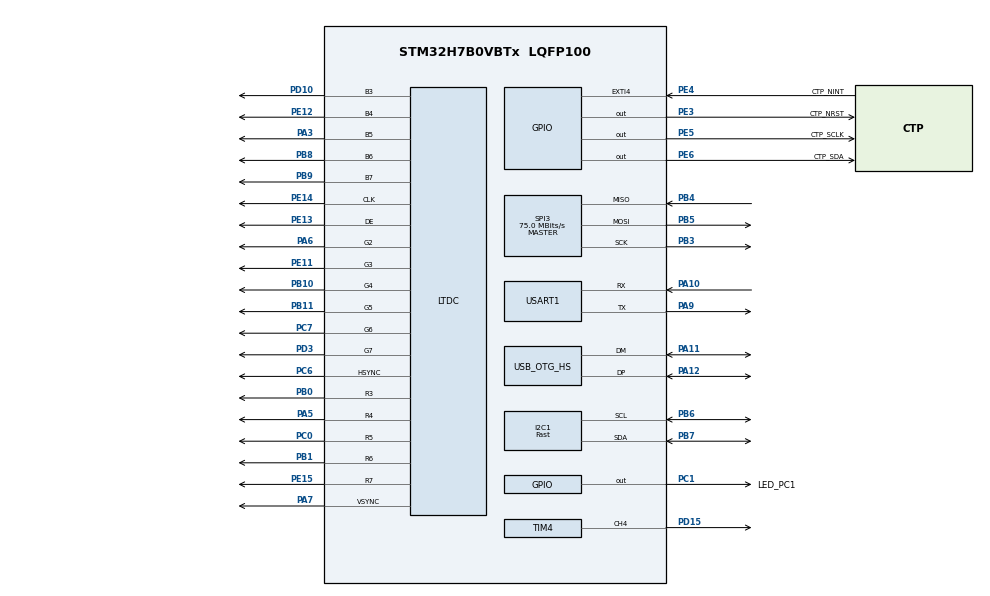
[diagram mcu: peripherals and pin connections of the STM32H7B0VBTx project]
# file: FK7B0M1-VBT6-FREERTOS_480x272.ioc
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CORTEX_M7.AccessPermission_S-Cortex_Memory_Protection_Unit_Region1_Settings_S=MPU_REGION_FULL_ACCESS
CORTEX_M7.AccessPermission_Spec=MPU_REGION_FULL_ACCESS
CORTEX_M7.BaseAddress_S-Cortex_Memory_Protection_Unit_Region1_Settings_S=0x24080000
CORTEX_M7.BaseAddress_Spec=0x24000000
CORTEX_M7.CPU_DCache=Enabled
CORTEX_M7.CPU_ICache=Enabled
CORTEX_M7.DisableExec_S-Cortex_Memory_Protection_Unit_Region1_Settings_S=MPU_INSTRUCTION_ACCESS_DISABLE
CORTEX_M7.DisableExec_Spec=MPU_INSTRUCTION_ACCESS_DISABLE
CORTEX_M7.Enable_S-Cortex_Memory_Protection_Unit_Region1_Settings_S=MPU_REGION_ENABLE
CORTEX_M7.IsBufferable_S-Cortex_Memory_Protection_Unit_Region1_Settings_S=MPU_ACCESS_BUFFERABLE
CORTEX_M7.IsBufferable_Spec=MPU_ACCESS_NOT_BUFFERABLE
CORTEX_M7.IsCacheable_S-Cortex_Memory_Protection_Unit_Region1_Settings_S=MPU_ACCESS_CACHEABLE
CORTEX_M7.IsCacheable_Spec=MPU_ACCESS_NOT_CACHEABLE
CORTEX_M7.IsShareable_S-Cortex_Memory_Protection_Unit_Region1_Settings_S=MPU_ACCESS_NOT_SHAREABLE
CORTEX_M7.IsShareable_Spec=MPU_ACCESS_SHAREABLE
CORTEX_M7.Size_S-Cortex_Memory_Protection_Unit_Region1_Settings_S=MPU_REGION_SIZE_512KB
CORTEX_M7.Size_Spec=MPU_REGION_SIZE_512KB
CORTEX_M7.SubRegionDisable_Spec=0x00
CORTEX_M7.TypeExtField_S-Cortex_Memory_Protection_Unit_Region1_Settings_S=MPU_TEX_LEVEL1
CORTEX_M7.TypeExtField_Spec=MPU_TEX_LEVEL1
CORTEX_M7.default_mode_Activation=1
FREERTOS.Tasks01=defaultTask,24,128,StartDefaultTask,Default,NULL,Dynamic,NULL,NULL
FREERTOS.configENABLE_FPU=1
FREERTOS.configTOTAL_HEAP_SIZE=32768
I2C1.I2C_Speed_Mode=I2C_Fast
I2C1.Timing=0x00D04BFF
LTDC.ActiveH=272
LTDC.ActiveW=480
LTDC.Alpha_L0=255
LTDC.BlendingFactor1_L0=LTDC_BLENDING_FACTOR1_CA
LTDC.BlendingFactor2_L0=LTDC_BLENDING_FACTOR2_CA
LTDC.DEPolarity=LTDC_DEPOLARITY_AL
LTDC.FBStartAdress_L0=0x24000000
LTDC.HBP=44
LTDC.HFP=8
LTDC.HSync=4
LTDC.ImageHeight_L0=272
LTDC.ImageWidth_L0=480
LTDC.Layers=0
LTDC.PCPolarity=LTDC_PCPOLARITY_IIPC
LTDC.PixelFormat_L0=LTDC_PIXEL_FORMAT_RGB565
LTDC.VBP=13
LTDC.VFP=2
LTDC.VSync=4
LTDC.WindowX1_L0=479
LTDC.WindowY1_L0=271
Mcu.Family=STM32H7
Mcu.Name=STM32H7B0VBTx
Mcu.Package=LQFP100
NVIC.DMA2D_IRQn=true\:5\:0\:false\:false\:true\:true\:true\:true\:true
NVIC.EXTI4_IRQn=true\:5\:0\:true\:false\:true\:false\:true\:true\:true
NVIC.I2C1_ER_IRQn=true\:5\:0\:false\:false\:true\:true\:true\:true\:true
NVIC.I2C1_EV_IRQn=true\:5\:0\:false\:false\:true\:true\:true\:true\:true
NVIC.LTDC_IRQn=true\:5\:0\:false\:false\:true\:true\:true\:true\:true
NVIC.OTG_HS_IRQn=true\:5\:0\:false\:false\:true\:true\:false\:true\:true
NVIC.PriorityGroup=NVIC_PRIORITYGROUP_4
NVIC.SPI3_IRQn=true\:5\:0\:false\:false\:true\:true\:true\:true\:true
NVIC.TIM8_UP_TIM13_IRQn=true\:15\:0\:false\:false\:true\:false\:false\:true\:true
NVIC.TimeBase=TIM8_UP_TIM13_IRQn
NVIC.TimeBaseIP=TIM8
PA1.Signal=LTDC_R2
PA10.Mode=Asynchronous
PA10.Signal=USART1_RX
PA11.Mode=Device_Only_FS
PA11.Signal=USB_OTG_HS_DM
PA12.Mode=Device_Only_FS
PA12.Signal=USB_OTG_HS_DP
PA13.Mode=Serial_Wire
PA13.Signal=DEBUG_JTMS-SWDIO
PA14.Mode=Serial_Wire
PA14.Signal=DEBUG_JTCK-SWCLK
PA15.Signal=SPI3_NSS
PA2.Signal=LTDC_R1
PA3.GPIO_Speed=GPIO_SPEED_FREQ_VERY_HIGH
PA3.Mode=RGB565
PA3.Signal=LTDC_B5
PA5.GPIO_Speed=GPIO_SPEED_FREQ_VERY_HIGH
PA5.Mode=RGB565
PA5.Signal=LTDC_R4
PA6.GPIO_Speed=GPIO_SPEED_FREQ_VERY_HIGH
PA6.Mode=RGB565
PA6.Signal=LTDC_G2
PA7.GPIO_Speed=GPIO_SPEED_FREQ_VERY_HIGH
PA7.Mode=RGB565
PA7.Signal=LTDC_VSYNC
PA9.Mode=Asynchronous
PA9.Signal=USART1_TX
PB0.GPIO_Speed=GPIO_SPEED_FREQ_VERY_HIGH
PB0.Mode=RGB565
PB0.Signal=LTDC_R3
PB1.GPIO_Speed=GPIO_SPEED_FREQ_VERY_HIGH
PB1.Mode=RGB565
PB1.Signal=LTDC_R6
PB10.GPIO_Speed=GPIO_SPEED_FREQ_VERY_HIGH
PB10.Mode=RGB565
PB10.Signal=LTDC_G4
PB11.GPIO_Speed=GPIO_SPEED_FREQ_VERY_HIGH
PB11.Mode=RGB565
PB11.Signal=LTDC_G5
PB3.Mode=Full_Duplex_Master
PB3.Signal=SPI3_SCK
PB4.Mode=Full_Duplex_Master
PB4.Signal=SPI3_MISO
PB5.Mode=Full_Duplex_Master
PB5.Signal=SPI3_MOSI
PB6.Mode=I2C
PB6.Signal=I2C1_SCL
PB7.Mode=I2C
PB7.Signal=I2C1_SDA
PB8.GPIO_FM8=__NULL
PB8.GPIO_Speed=GPIO_SPEED_FREQ_VERY_HIGH
PB8.Mode=RGB565
PB8.Signal=LTDC_B6
PB9.GPIO_Speed=GPIO_SPEED_FREQ_VERY_HIGH
PB9.Mode=RGB565
PB9.Signal=LTDC_B7
PC0.GPIO_Speed=GPIO_SPEED_FREQ_VERY_HIGH
PC0.Mode=RGB565
PC0.Signal=LTDC_R5
PC1.GPIO_Label=LED_PC1
PC1.Signal=GPIO_Output
PC14-OSC32_IN.Mode=LSE-External-Oscillator
PC14-OSC32_IN.Signal=RCC_OSC32_IN
PC15-OSC32_OUT.Mode=LSE-External-Oscillator
PC15-OSC32_OUT.Signal=RCC_OSC32_OUT
PC6.GPIO_Speed=GPIO_SPEED_FREQ_VERY_HIGH
PC6.Mode=RGB565
PC6.Signal=LTDC_HSYNC
PC7.GPIO_Speed=GPIO_SPEED_FREQ_VERY_HIGH
PC7.Mode=RGB565
PC7.Signal=LTDC_G6
PD10.GPIO_Speed=GPIO_SPEED_FREQ_VERY_HIGH
PD10.Mode=RGB565
PD10.Signal=LTDC_B3
PD15.Signal=S_TIM4_CH4
PD3.GPIO_Speed=GPIO_SPEED_FREQ_VERY_HIGH
PD3.Mode=RGB565
PD3.Signal=LTDC_G7
PD6.Signal=LTDC_B2
PE11.GPIO_Speed=GPIO_SPEED_FREQ_VERY_HIGH
PE11.Mode=RGB565
PE11.Signal=LTDC_G3
PE12.GPIO_Speed=GPIO_SPEED_FREQ_VERY_HIGH
PE12.Mode=RGB565
PE12.Signal=LTDC_B4
PE13.GPIO_Speed=GPIO_SPEED_FREQ_VERY_HIGH
PE13.Mode=RGB565
PE13.Signal=LTDC_DE
PE14.GPIO_Speed=GPIO_SPEED_FREQ_VERY_HIGH
PE14.Mode=RGB565
PE14.Signal=LTDC_CLK
PE15.GPIO_Speed=GPIO_SPEED_FREQ_VERY_HIGH
PE15.Mode=RGB565
PE15.Signal=LTDC_R7
PE3.GPIO_Label=CTP_NRST
PE3.GPIO_PuPd=GPIO_PULLUP
PE3.GPIO_Speed=GPIO_SPEED_FREQ_VERY_HIGH
PE3.Signal=GPIO_Output
PE4.GPIO_Label=CTP_NINT
PE4.GPIO_ModeDefaultEXTI=GPIO_MODE_IT_FALLING
PE4.GPIO_PuPd=GPIO_PULLUP
PE4.Signal=GPXTI4
PE5.GPIO_Label=CTP_SCLK
PE5.GPIO_PuPd=GPIO_PULLUP
PE5.GPIO_Speed=GPIO_SPEED_FREQ_VERY_HIGH
PE5.PinState=GPIO_PIN_SET
PE5.Signal=GPIO_Output
PE6.GPIO_Label=CTP_SDA
PE6.GPIO_PuPd=GPIO_PULLUP
PE6.GPIO_Speed=GPIO_SPEED_FREQ_VERY_HIGH
PE6.PinState=GPIO_PIN_SET
PE6.Signal=GPIO_Output
PH0-OSC_IN.Mode=HSE-External-Oscillator
PH0-OSC_IN.Signal=RCC_OSC_IN
PH1-OSC_OUT.Mode=HSE-External-Oscillator
PH1-OSC_OUT.Signal=RCC_OSC_OUT
ProjectManager.HeapSize=0x200
ProjectManager.StackSize=0x400
ProjectManager.TargetToolchain=Makefile
RCC.ADCFreq_Value=50390625
RCC.APB1Freq_Value=140000000
RCC.APB2Freq_Value=140000000
RCC.APB3Freq_Value=140000000
RCC.APB4Freq_Value=140000000
RCC.CDPPRE=RCC_APB3_DIV2
RCC.CDPPRE1=RCC_APB1_DIV2
RCC.CDPPRE2=RCC_APB2_DIV2
RCC.CortexFreq_Value=280000000
RCC.DIVM1=5
RCC.DIVM3=2
RCC.DIVN1=112
RCC.DIVN3=24
RCC.DIVQ1=12
RCC.DIVR3=25
RCC.HCLKFreq_Value=280000000
RCC.HSE_VALUE=25000000
RCC.PLL2FRACN=0
RCC.PLL3FRACN=0
RCC.PLLFRACN=0
RCC.PLLSourceVirtual=RCC_PLLSOURCE_HSE
RCC.SPI123CLockSelection=RCC_SPI123CLKSOURCE_PLL3
RCC.SRDPPRE=RCC_APB4_DIV2
RCC.SYSCLKFreq_VALUE=280000000
RCC.SYSCLKSource=RCC_SYSCLKSOURCE_PLLCLK
RCC.USBCLockSelection=RCC_USBCLKSOURCE_HSI48
RCC.USBFreq_Value=48000000
SH.S_TIM4_CH4.0=TIM4_CH4,PWM Generation4 CH4
SPI3.CalculateBaudRate=75.0 MBits/s
SPI3.Direction=SPI_DIRECTION_2LINES
SPI3.Mode=SPI_MODE_MASTER
SPI3.VirtualType=VM_MASTER
TIM4.AutoReloadPreload=TIM_AUTORELOAD_PRELOAD_ENABLE
TIM4.Channel-PWM\ Generation4\ CH4=TIM_CHANNEL_4
TIM4.Period=999
TIM4.Prescaler=27
TIM4.Pulse-PWM\ Generation4\ CH4=300
USART1.VirtualMode-Asynchronous=VM_ASYNC
USB_DEVICE.CLASS_NAME_HS=CDC
USB_DEVICE.VirtualMode=Cdc
USB_DEVICE.VirtualModeHS=Cdc_HS
USB_OTG_HS.VirtualMode-Device_Only_FS=Device_Only_FS
VP_DMA2D_VS_DMA2D.Mode=DMA2D_Activate
VP_FREERTOS_VS_CMSIS_V2.Mode=CMSIS_V2
VP_MEMORYMAP_VS_MEMORYMAP.Mode=CurAppReg
VP_SYS_VS_tim8.Mode=TIM8
VP_TIM4_VS_ClockSourceINT.Mode=Internal
VP_USB_DEVICE_VS_USB_DEVICE_CDC_HS.Mode=CDC_HS
board=custom

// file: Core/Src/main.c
/* USER CODE BEGIN Header */
/**
  ******************************************************************************
  * @file           : main.c
  * @brief          : Main program body
  ******************************************************************************
  * @attention
  *
  * Copyright (c) 2026 STMicroelectronics.
  * All rights reserved.
  *
  * This software is licensed under terms that can be found in the LICENSE file
  * in the root directory of this software component.
  * If no LICENSE file comes with this software, it is provided AS-IS.
  *
  ******************************************************************************
  */
/* USER CODE END Header */
#include "main.h"
#include "FreeRTOS.h"
#include "cmsis_os2.h"
#include "usb_device.h"

/* USER CODE BEGIN Includes */
#include "app.h"
/* USER CODE END Includes */

DMA2D_HandleTypeDef hdma2d;

I2C_HandleTypeDef hi2c1;

LTDC_HandleTypeDef hltdc;

SPI_HandleTypeDef hspi3;

TIM_HandleTypeDef htim4;

UART_HandleTypeDef huart1;

/* Definitions for defaultTask */
osThreadId_t defaultTaskHandle;
const osThreadAttr_t defaultTask_attributes = {
  .name = "defaultTask",
  .stack_size = 128 * 4,
  .priority = (osPriority_t) osPriorityNormal,
};

void SystemClock_Config(void);
void PeriphCommonClock_Config(void);
static void MPU_Config(void);
static void MX_GPIO_Init(void);
static void MX_LTDC_Init(void);
static void MX_SPI3_Init(void);
static void MX_USART1_UART_Init(void);
static void MX_I2C1_Init(void);
static void MX_TIM4_Init(void);
static void MX_DMA2D_Init(void);
void StartDefaultTask(void *argument);

int main(void)
{

  /* MPU Configuration--------------------------------------------------------*/
  MPU_Config();

  /* Enable the CPU Cache */

  /* Enable I-Cache---------------------------------------------------------*/
  SCB_EnableICache();

  /* Enable D-Cache---------------------------------------------------------*/
  SCB_EnableDCache();

  /* MCU Configuration--------------------------------------------------------*/

  /* Reset of all peripherals, Initializes the Flash interface and the Systick. */
  HAL_Init();

  /* Configure the system clock */
  SystemClock_Config();

  /* Configure the peripherals common clocks */
  PeriphCommonClock_Config();

  /* Initialize all configured peripherals */
  MX_GPIO_Init();
  MX_LTDC_Init();
  MX_SPI3_Init();
  MX_USART1_UART_Init();
  MX_I2C1_Init();
  MX_TIM4_Init();
  MX_DMA2D_Init();

  /* Init scheduler */
  osKernelInitialize();

  /* USER CODE BEGIN RTOS_MUTEX */
  app_init();
  /* USER CODE END RTOS_MUTEX */

  /* Create the thread(s) */
  /* creation of defaultTask */
  defaultTaskHandle = osThreadNew(StartDefaultTask, NULL, &defaultTask_attributes);

  /* Start scheduler */
  osKernelStart();

  /* We should never get here as control is now taken by the scheduler */

  /* Infinite loop */
  while (1)
  {

  }
}

void SystemClock_Config(void)
{
  RCC_OscInitTypeDef RCC_OscInitStruct = {0};
  RCC_ClkInitTypeDef RCC_ClkInitStruct = {0};

  /*AXI clock gating */
  RCC->CKGAENR = 0xE003FFFF;

  /** Supply configuration update enable
  */
  HAL_PWREx_ConfigSupply(PWR_LDO_SUPPLY);

  /** Configure the main internal regulator output voltage
  */
  __HAL_PWR_VOLTAGESCALING_CONFIG(PWR_REGULATOR_VOLTAGE_SCALE0);

  while(!__HAL_PWR_GET_FLAG(PWR_FLAG_VOSRDY)) {}

  /** Initializes the RCC Oscillators according to the specified parameters
  * in the RCC_OscInitTypeDef structure.
  */
  RCC_OscInitStruct.OscillatorType = RCC_OSCILLATORTYPE_HSI48|RCC_OSCILLATORTYPE_HSE;
  RCC_OscInitStruct.HSEState = RCC_HSE_ON;
  RCC_OscInitStruct.HSI48State = RCC_HSI48_ON;
  RCC_OscInitStruct.PLL.PLLState = RCC_PLL_ON;
  RCC_OscInitStruct.PLL.PLLSource = RCC_PLLSOURCE_HSE;
  RCC_OscInitStruct.PLL.PLLM = 5;
  RCC_OscInitStruct.PLL.PLLN = 112;
  RCC_OscInitStruct.PLL.PLLP = 2;
  RCC_OscInitStruct.PLL.PLLQ = 12;
  RCC_OscInitStruct.PLL.PLLR = 2;
  RCC_OscInitStruct.PLL.PLLRGE = RCC_PLL1VCIRANGE_2;
  RCC_OscInitStruct.PLL.PLLVCOSEL = RCC_PLL1VCOWIDE;
  RCC_OscInitStruct.PLL.PLLFRACN = 0;
  if (HAL_RCC_OscConfig(&RCC_OscInitStruct) != HAL_OK)
  {
    Error_Handler();
  }

  /** Initializes the CPU, AHB and APB buses clocks
  */
  RCC_ClkInitStruct.ClockType = RCC_CLOCKTYPE_HCLK|RCC_CLOCKTYPE_SYSCLK
                              |RCC_CLOCKTYPE_PCLK1|RCC_CLOCKTYPE_PCLK2
                              |RCC_CLOCKTYPE_D3PCLK1|RCC_CLOCKTYPE_D1PCLK1;
  RCC_ClkInitStruct.SYSCLKSource = RCC_SYSCLKSOURCE_PLLCLK;
  RCC_ClkInitStruct.SYSCLKDivider = RCC_SYSCLK_DIV1;
  RCC_ClkInitStruct.AHBCLKDivider = RCC_HCLK_DIV1;
  RCC_ClkInitStruct.APB3CLKDivider = RCC_APB3_DIV2;
  RCC_ClkInitStruct.APB1CLKDivider = RCC_APB1_DIV2;
  RCC_ClkInitStruct.APB2CLKDivider = RCC_APB2_DIV2;
  RCC_ClkInitStruct.APB4CLKDivider = RCC_APB4_DIV2;

  if (HAL_RCC_ClockConfig(&RCC_ClkInitStruct, FLASH_LATENCY_6) != HAL_OK)
  {
    Error_Handler();
  }
}

void PeriphCommonClock_Config(void)
{
  RCC_PeriphCLKInitTypeDef PeriphClkInitStruct = {0};

  /** Initializes the peripherals clock
  */
  PeriphClkInitStruct.PeriphClockSelection = RCC_PERIPHCLK_SPI3|RCC_PERIPHCLK_LTDC;
  PeriphClkInitStruct.PLL3.PLL3M = 2;
  PeriphClkInitStruct.PLL3.PLL3N = 24;
  PeriphClkInitStruct.PLL3.PLL3P = 2;
  PeriphClkInitStruct.PLL3.PLL3Q = 2;
  PeriphClkInitStruct.PLL3.PLL3R = 25;
  PeriphClkInitStruct.PLL3.PLL3RGE = RCC_PLL3VCIRANGE_3;
  PeriphClkInitStruct.PLL3.PLL3VCOSEL = RCC_PLL3VCOWIDE;
  PeriphClkInitStruct.PLL3.PLL3FRACN = 0;
  PeriphClkInitStruct.Spi123ClockSelection = RCC_SPI123CLKSOURCE_PLL3;
  if (HAL_RCCEx_PeriphCLKConfig(&PeriphClkInitStruct) != HAL_OK)
  {
    Error_Handler();
  }
}

static void MX_DMA2D_Init(void)
{

  hdma2d.Instance = DMA2D;
  hdma2d.Init.Mode = DMA2D_M2M;
  hdma2d.Init.ColorMode = DMA2D_OUTPUT_ARGB8888;
  hdma2d.Init.OutputOffset = 0;
  hdma2d.LayerCfg[1].InputOffset = 0;
  hdma2d.LayerCfg[1].InputColorMode = DMA2D_INPUT_ARGB8888;
  hdma2d.LayerCfg[1].AlphaMode = DMA2D_NO_MODIF_ALPHA;
  hdma2d.LayerCfg[1].InputAlpha = 0;
  hdma2d.LayerCfg[1].AlphaInverted = DMA2D_REGULAR_ALPHA;
  hdma2d.LayerCfg[1].RedBlueSwap = DMA2D_RB_REGULAR;
  hdma2d.LayerCfg[1].ChromaSubSampling = DMA2D_NO_CSS;
  if (HAL_DMA2D_Init(&hdma2d) != HAL_OK)
  {
    Error_Handler();
  }
  if (HAL_DMA2D_ConfigLayer(&hdma2d, 1) != HAL_OK)
  {
    Error_Handler();
  }

}

static void MX_I2C1_Init(void)
{

  hi2c1.Instance = I2C1;
  hi2c1.Init.Timing = 0x00D04BFF;
  hi2c1.Init.OwnAddress1 = 0;
  hi2c1.Init.AddressingMode = I2C_ADDRESSINGMODE_7BIT;
  hi2c1.Init.DualAddressMode = I2C_DUALADDRESS_DISABLE;
  hi2c1.Init.OwnAddress2 = 0;
  hi2c1.Init.OwnAddress2Masks = I2C_OA2_NOMASK;
  hi2c1.Init.GeneralCallMode = I2C_GENERALCALL_DISABLE;
  hi2c1.Init.NoStretchMode = I2C_NOSTRETCH_DISABLE;
  if (HAL_I2C_Init(&hi2c1) != HAL_OK)
  {
    Error_Handler();
  }

  /** Configure Analogue filter
  */
  if (HAL_I2CEx_ConfigAnalogFilter(&hi2c1, I2C_ANALOGFILTER_ENABLE) != HAL_OK)
  {
    Error_Handler();
  }

  /** Configure Digital filter
  */
  if (HAL_I2CEx_ConfigDigitalFilter(&hi2c1, 0) != HAL_OK)
  {
    Error_Handler();
  }

}

static void MX_LTDC_Init(void)
{

  LTDC_LayerCfgTypeDef pLayerCfg = {0};

  hltdc.Instance = LTDC;
  hltdc.Init.HSPolarity = LTDC_HSPOLARITY_AL;
  hltdc.Init.VSPolarity = LTDC_VSPOLARITY_AL;
  hltdc.Init.DEPolarity = LTDC_DEPOLARITY_AL;
  hltdc.Init.PCPolarity = LTDC_PCPOLARITY_IIPC;
  hltdc.Init.HorizontalSync = 3;
  hltdc.Init.VerticalSync = 3;
  hltdc.Init.AccumulatedHBP = 47;
  hltdc.Init.AccumulatedVBP = 16;
  hltdc.Init.AccumulatedActiveW = 527;
  hltdc.Init.AccumulatedActiveH = 288;
  hltdc.Init.TotalWidth = 535;
  hltdc.Init.TotalHeigh = 290;
  hltdc.Init.Backcolor.Blue = 0;
  hltdc.Init.Backcolor.Green = 0;
  hltdc.Init.Backcolor.Red = 0;
  if (HAL_LTDC_Init(&hltdc) != HAL_OK)
  {
    Error_Handler();
  }
  pLayerCfg.WindowX0 = 0;
  pLayerCfg.WindowX1 = 479;
  pLayerCfg.WindowY0 = 0;
  pLayerCfg.WindowY1 = 271;
  pLayerCfg.PixelFormat = LTDC_PIXEL_FORMAT_RGB565;
  pLayerCfg.Alpha = 255;
  pLayerCfg.Alpha0 = 0;
  pLayerCfg.BlendingFactor1 = LTDC_BLENDING_FACTOR1_CA;
  pLayerCfg.BlendingFactor2 = LTDC_BLENDING_FACTOR2_CA;
  pLayerCfg.FBStartAdress = 0x24000000;
  pLayerCfg.ImageWidth = 480;
  pLayerCfg.ImageHeight = 272;
  pLayerCfg.Backcolor.Blue = 0;
  pLayerCfg.Backcolor.Green = 0;
  pLayerCfg.Backcolor.Red = 0;
  if (HAL_LTDC_ConfigLayer(&hltdc, &pLayerCfg, 0) != HAL_OK)
  {
    Error_Handler();
  }

}

static void MX_SPI3_Init(void)
{

  /* SPI3 parameter configuration*/
  hspi3.Instance = SPI3;
  hspi3.Init.Mode = SPI_MODE_MASTER;
  hspi3.Init.Direction = SPI_DIRECTION_2LINES;
  hspi3.Init.DataSize = SPI_DATASIZE_4BIT;
  hspi3.Init.CLKPolarity = SPI_POLARITY_LOW;
  hspi3.Init.CLKPhase = SPI_PHASE_1EDGE;
  hspi3.Init.NSS = SPI_NSS_SOFT;
  hspi3.Init.BaudRatePrescaler = SPI_BAUDRATEPRESCALER_2;
  hspi3.Init.FirstBit = SPI_FIRSTBIT_MSB;
  hspi3.Init.TIMode = SPI_TIMODE_DISABLE;
  hspi3.Init.CRCCalculation = SPI_CRCCALCULATION_DISABLE;
  hspi3.Init.CRCPolynomial = 0x0;
  hspi3.Init.NSSPMode = SPI_NSS_PULSE_ENABLE;
  hspi3.Init.NSSPolarity = SPI_NSS_POLARITY_LOW;
  hspi3.Init.FifoThreshold = SPI_FIFO_THRESHOLD_01DATA;
  hspi3.Init.TxCRCInitializationPattern = SPI_CRC_INITIALIZATION_ALL_ZERO_PATTERN;
  hspi3.Init.RxCRCInitializationPattern = SPI_CRC_INITIALIZATION_ALL_ZERO_PATTERN;
  hspi3.Init.MasterSSIdleness = SPI_MASTER_SS_IDLENESS_00CYCLE;
  hspi3.Init.MasterInterDataIdleness = SPI_MASTER_INTERDATA_IDLENESS_00CYCLE;
  hspi3.Init.MasterReceiverAutoSusp = SPI_MASTER_RX_AUTOSUSP_DISABLE;
  hspi3.Init.MasterKeepIOState = SPI_MASTER_KEEP_IO_STATE_DISABLE;
  hspi3.Init.IOSwap = SPI_IO_SWAP_DISABLE;
  if (HAL_SPI_Init(&hspi3) != HAL_OK)
  {
    Error_Handler();
  }

}

static void MX_TIM4_Init(void)
{

  TIM_ClockConfigTypeDef sClockSourceConfig = {0};
  TIM_MasterConfigTypeDef sMasterConfig = {0};
  TIM_OC_InitTypeDef sConfigOC = {0};

  htim4.Instance = TIM4;
  htim4.Init.Prescaler = 27;
  htim4.Init.CounterMode = TIM_COUNTERMODE_UP;
  htim4.Init.Period = 999;
  htim4.Init.ClockDivision = TIM_CLOCKDIVISION_DIV1;
  htim4.Init.AutoReloadPreload = TIM_AUTORELOAD_PRELOAD_ENABLE;
  if (HAL_TIM_Base_Init(&htim4) != HAL_OK)
  {
    Error_Handler();
  }
  sClockSourceConfig.ClockSource = TIM_CLOCKSOURCE_INTERNAL;
  if (HAL_TIM_ConfigClockSource(&htim4, &sClockSourceConfig) != HAL_OK)
  {
    Error_Handler();
  }
  if (HAL_TIM_PWM_Init(&htim4) != HAL_OK)
  {
    Error_Handler();
  }
  sMasterConfig.MasterOutputTrigger = TIM_TRGO_RESET;
  sMasterConfig.MasterSlaveMode = TIM_MASTERSLAVEMODE_DISABLE;
  if (HAL_TIMEx_MasterConfigSynchronization(&htim4, &sMasterConfig) != HAL_OK)
  {
    Error_Handler();
  }
  sConfigOC.OCMode = TIM_OCMODE_PWM1;
  sConfigOC.Pulse = 300;
  sConfigOC.OCPolarity = TIM_OCPOLARITY_HIGH;
  sConfigOC.OCFastMode = TIM_OCFAST_DISABLE;
  if (HAL_TIM_PWM_ConfigChannel(&htim4, &sConfigOC, TIM_CHANNEL_4) != HAL_OK)
  {
    Error_Handler();
  }
  HAL_TIM_MspPostInit(&htim4);

}

static void MX_USART1_UART_Init(void)
{

  huart1.Instance = USART1;
  huart1.Init.BaudRate = 115200;
  huart1.Init.WordLength = UART_WORDLENGTH_8B;
  huart1.Init.StopBits = UART_STOPBITS_1;
  huart1.Init.Parity = UART_PARITY_NONE;
  huart1.Init.Mode = UART_MODE_TX_RX;
  huart1.Init.HwFlowCtl = UART_HWCONTROL_NONE;
  huart1.Init.OverSampling = UART_OVERSAMPLING_16;
  huart1.Init.OneBitSampling = UART_ONE_BIT_SAMPLE_DISABLE;
  huart1.Init.ClockPrescaler = UART_PRESCALER_DIV1;
  huart1.AdvancedInit.AdvFeatureInit = UART_ADVFEATURE_NO_INIT;
  if (HAL_UART_Init(&huart1) != HAL_OK)
  {
    Error_Handler();
  }
  if (HAL_UARTEx_SetTxFifoThreshold(&huart1, UART_TXFIFO_THRESHOLD_1_8) != HAL_OK)
  {
    Error_Handler();
  }
  if (HAL_UARTEx_SetRxFifoThreshold(&huart1, UART_RXFIFO_THRESHOLD_1_8) != HAL_OK)
  {
    Error_Handler();
  }
  if (HAL_UARTEx_DisableFifoMode(&huart1) != HAL_OK)
  {
    Error_Handler();
  }

}

static void MX_GPIO_Init(void)
{
  GPIO_InitTypeDef GPIO_InitStruct = {0};

  /* GPIO Ports Clock Enable */
  __HAL_RCC_GPIOE_CLK_ENABLE();
  __HAL_RCC_GPIOC_CLK_ENABLE();
  __HAL_RCC_GPIOH_CLK_ENABLE();
  __HAL_RCC_GPIOA_CLK_ENABLE();
  __HAL_RCC_GPIOB_CLK_ENABLE();
  __HAL_RCC_GPIOD_CLK_ENABLE();

  /*Configure GPIO pin Output Level */
  HAL_GPIO_WritePin(CTP_NRST_GPIO_Port, CTP_NRST_Pin, GPIO_PIN_RESET);

  /*Configure GPIO pin Output Level */
  HAL_GPIO_WritePin(GPIOE, CTP_SCLK_Pin|CTP_SDA_Pin, GPIO_PIN_SET);

  /*Configure GPIO pin Output Level */
  HAL_GPIO_WritePin(LED_PC1_GPIO_Port, LED_PC1_Pin, GPIO_PIN_RESET);

  /*Configure GPIO pins : CTP_NRST_Pin CTP_SCLK_Pin CTP_SDA_Pin */
  GPIO_InitStruct.Pin = CTP_NRST_Pin|CTP_SCLK_Pin|CTP_SDA_Pin;
  GPIO_InitStruct.Mode = GPIO_MODE_OUTPUT_PP;
  GPIO_InitStruct.Pull = GPIO_PULLUP;
  GPIO_InitStruct.Speed = GPIO_SPEED_FREQ_VERY_HIGH;
  HAL_GPIO_Init(GPIOE, &GPIO_InitStruct);

  /*Configure GPIO pin : CTP_NINT_Pin */
  GPIO_InitStruct.Pin = CTP_NINT_Pin;
  GPIO_InitStruct.Mode = GPIO_MODE_IT_FALLING;
  GPIO_InitStruct.Pull = GPIO_PULLUP;
  HAL_GPIO_Init(CTP_NINT_GPIO_Port, &GPIO_InitStruct);

  /*Configure GPIO pin : LED_PC1_Pin */
  GPIO_InitStruct.Pin = LED_PC1_Pin;
  GPIO_InitStruct.Mode = GPIO_MODE_OUTPUT_PP;
  GPIO_InitStruct.Pull = GPIO_NOPULL;
  GPIO_InitStruct.Speed = GPIO_SPEED_FREQ_LOW;
  HAL_GPIO_Init(LED_PC1_GPIO_Port, &GPIO_InitStruct);

  /* EXTI interrupt init*/
  HAL_NVIC_SetPriority(CTP_NINT_EXTI_IRQn, 5, 0);
  HAL_NVIC_EnableIRQ(CTP_NINT_EXTI_IRQn);

}

void StartDefaultTask(void *argument)
{
  /* init code for USB_DEVICE */
  MX_USB_DEVICE_Init();
  for(;;)
  {
    osDelay(1);
  }
}

 /* MPU Configuration */

void MPU_Config(void)
{
  MPU_Region_InitTypeDef MPU_InitStruct = {0};

  /* Disables the MPU */
  HAL_MPU_Disable();

  /** Initializes and configures the Region and the memory to be protected
  */
  MPU_InitStruct.Enable = MPU_REGION_ENABLE;
  MPU_InitStruct.Number = MPU_REGION_NUMBER0;
  MPU_InitStruct.BaseAddress = 0x24000000;
  MPU_InitStruct.Size = MPU_REGION_SIZE_512KB;
  MPU_InitStruct.SubRegionDisable = 0x00;
  MPU_InitStruct.TypeExtField = MPU_TEX_LEVEL1;
  MPU_InitStruct.AccessPermission = MPU_REGION_FULL_ACCESS;
  MPU_InitStruct.DisableExec = MPU_INSTRUCTION_ACCESS_DISABLE;
  MPU_InitStruct.IsShareable = MPU_ACCESS_SHAREABLE;
  MPU_InitStruct.IsCacheable = MPU_ACCESS_NOT_CACHEABLE;
  MPU_InitStruct.IsBufferable = MPU_ACCESS_NOT_BUFFERABLE;

  HAL_MPU_ConfigRegion(&MPU_InitStruct);

  /** Initializes and configures the Region and the memory to be protected
  */
  MPU_InitStruct.Number = MPU_REGION_NUMBER1;
  MPU_InitStruct.BaseAddress = 0x24080000;
  MPU_InitStruct.SubRegionDisable = 0x0;
  MPU_InitStruct.IsShareable = MPU_ACCESS_NOT_SHAREABLE;
  MPU_InitStruct.IsCacheable = MPU_ACCESS_CACHEABLE;
  MPU_InitStruct.IsBufferable = MPU_ACCESS_BUFFERABLE;

  HAL_MPU_ConfigRegion(&MPU_InitStruct);
  /* Enables the MPU */
  HAL_MPU_Enable(MPU_PRIVILEGED_DEFAULT);

}

void HAL_TIM_PeriodElapsedCallback(TIM_HandleTypeDef *htim)
{
  if (htim->Instance == TIM8)
  {
    HAL_IncTick();
  }
}

void Error_Handler(void)
{
  __disable_irq();
  while (1)
  {
  }
}
